# CC1314R10 register map
File version: 1.0
CPU: CM33 1.0, other endian, MPU, FPU, 3 interrupt priority bits
Registers are 32-bit, read-write, reset 0x0 unless marked. A register's access mark holds for its fields unless they carry their own. Offsets are from the block's base; [hi:lo] are bit positions.

## CPU_DCB — Cortex-M's Debug Control Block
Base 0xE000EDE0
0x10 DHCSR — Controls halting debug
  [26] S_RESTART_ST ro — [26:26] Indicates the PE has processed a request to clear DHCSR.C_HALT to 0. That is, either a write to DHCSR that clears DHCSR.C_HALT from 1 to 0, or an External Restart Request
  [25] S_RESET_ST ro — [25:25] Indicates whether the PE has been reset since the last read of the DHCSR
  [24] S_RETIRE_ST ro — [24:24] Set to 1 every time the PE retires one of more instructions
  [20] S_SDE ro — [20:20] Indicates whether Secure invasive debug is allowed
  [19] S_LOCKUP ro — [19:19] Indicates whether the PE is in Lockup state
  [18] S_SLEEP ro — [18:18] Indicates whether the PE is sleeping
  [17] S_HALT ro — [17:17] Indicates whether the PE is in Debug state
  [31:16] DBGKEY wo — [31:16] A debugger must write 0xA05F to this field to enable write access to the remaining bits, otherwise the PE ignores the write access
  [5] C_SNAPSTALL ro — [5:5] Allow imprecise entry to Debug state
  [3] C_MASKINTS — [3:3] When debug is enabled, the debugger can write to this bit to mask PendSV, SysTick and external configurable interrupts
  [2] C_STEP — [2:2] Enable single instruction step
  [1] C_HALT — [1:1] PE enter Debug state halt request
  [0] C_DEBUGEN — [0:0] Enable Halting debug
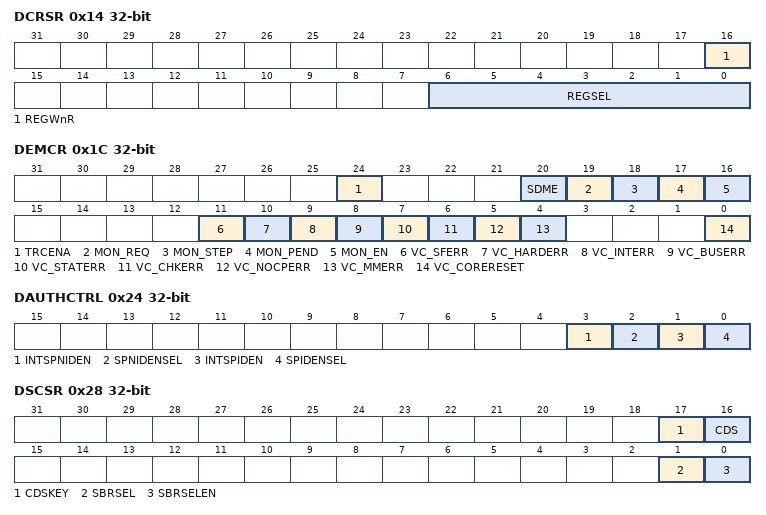
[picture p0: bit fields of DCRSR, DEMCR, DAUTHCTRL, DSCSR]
0x14 DCRSR — With the DCRDR, provides debug access to the general-purpose registers, special-purpose registers, and the FP extension registers. A write to the DCRSR specifies the register to transfer, whether the transfer is a read or write, and starts the transfer
  [16] REGWnR wo — [16:16] Specifies the access type for the transfer
  [6:0] REGSEL wo — [6:0] Specifies the general-purpose register, special-purpose register, or FP register to transfer
0x18 DCRDR — With the DCRSR, provides debug access to the general-purpose registers, special-purpose registers, and the FP Extension registers. If the Main Extension is implemented, it can also be used for message passing between an external debugger and a debug agent running on the PE
  [31:0] DBGTMP — [31:0] Provides debug access for reading and writing the general-purpose registers, special-purpose registers, and Floating-point Extension registers
0x1C DEMCR — Manages vector catch behavior and DebugMonitor handling when debugging
  [24] TRCENA — [24:24] Global enable for all DWT and ITM features
  [20] SDME ro — [20:20] Indicates whether the DebugMonitor targets the Secure or the Non-secure state and whether debug events are allowed in Secure state
  [19] MON_REQ ro — [19:19] DebugMonitor semaphore bit
  [18] MON_STEP ro — [18:18] Enable DebugMonitor stepping
  [17] MON_PEND ro — [17:17] Sets or clears the pending state of the DebugMonitor exception
  [16] MON_EN ro — [16:16] Enable the DebugMonitor exception
  [11] VC_SFERR ro — [11:11] SecureFault exception halting debug vector catch enable
  [10] VC_HARDERR — [10:10] HardFault exception halting debug vector catch enable
  [9] VC_INTERR ro — [9:9] Enable halting debug vector catch for faults during exception entry and return
  [8] VC_BUSERR ro — [8:8] BusFault exception halting debug vector catch enable
  [7] VC_STATERR ro — [7:7] Enable halting debug trap on a UsageFault exception caused by a state information error, for example an Undefined Instruction exception
  [6] VC_CHKERR ro — [6:6] Enable halting debug trap on a UsageFault exception caused by a checking error, for example an alignment check error
  [5] VC_NOCPERR ro — [5:5] Enable halting debug trap on a UsageFault caused by an access to a coprocessor
  [4] VC_MMERR ro — [4:4] Enable halting debug trap on a MemManage exception
  [0] VC_CORERESET — [0:0] Enable Reset Vector Catch. This causes a warm reset to halt a running system
0x24 DAUTHCTRL — This register allows the external authentication interface to be overridden from software.
  [3] INTSPNIDEN — [3:3] Internal Secure non-invasive debug enable. Overrides the external Secure non-invasive debug authentication interface
  [2] SPNIDENSEL — [2:2] Secure non-invasive debug enable select. Selects between DAUTHCTRL and the external authentication interface for control of Secure non-invasive debug
  [1] INTSPIDEN — [1:1] Internal Secure invasive debug enable. Overrides the external Secure invasive debug authentication Interfaces.
  [0] SPIDENSEL — [0:0] Secure invasive debug enable select. Selects between DAUTHCTRL and the external authentication interface for control of Secure invasive debug.
0x28 DSCSR — Provides control and status information for Secure debug
  [17] CDSKEY — [17:17] Writes to the CDS bit are ignored unless CDSKEY is concurrently written to zero
  [16] CDS — [16:16] This field indicates the current Security state of the processor
  [1] SBRSEL — [1:1] If SBRSELEN is 1 this bit selects whether the Non-secure or the Secure version of the memory-mapped Banked registers are accessible to the debugger
  [0] SBRSELEN — [0:0] Controls whether the SBRSEL field or the current Security state of the processor selects which version of the memory-mapped Banked registers are accessed to the debugger
